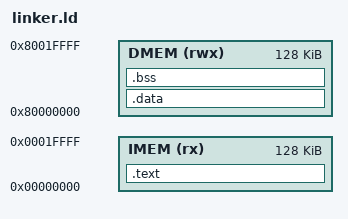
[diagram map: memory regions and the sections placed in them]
OUTPUT_ARCH(riscv)
ENTRY(_start)

MEMORY
{
    IMEM (rx)  : ORIGIN = 0x00000000, LENGTH = 128K
    DMEM (rwx) : ORIGIN = 0x80000000, LENGTH = 128K
}

SECTIONS
{
    .text :
    {
        . = ALIGN(4);

        /* Keep the reset entry at the beginning of IMEM. */
        KEEP(*(.text.start))
        KEEP(*(.text._start))

        *(.text*)
        . = ALIGN(4);
    } > IMEM

    .data :
    {
        . = ALIGN(4);
        *(.rodata*)
        *(.srodata*)
        *(.data*)
        *(.sdata*)
        . = ALIGN(4);
    } > DMEM

    .bss (NOLOAD) :
    {
        . = ALIGN(4);
        __bss_start = .;
        *(.bss*)
        *(.sbss*)
        *(COMMON)
        . = ALIGN(4);
        __bss_end = .;
    } > DMEM

    __stack_top = ORIGIN(DMEM) + LENGTH(DMEM);

    /DISCARD/ :
    {
        *(.comment)
        *(.note*)
        *(.eh_frame*)
        *(.riscv.attributes)
    }
}
